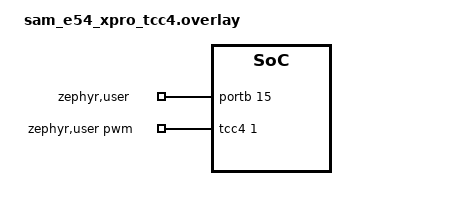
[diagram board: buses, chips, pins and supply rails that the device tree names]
/*
 * SPDX-FileCopyrightText: Copyright 2026 Microchip Technology Inc.
 * SPDX-License-Identifier: Apache-2.0
 */

/* connect PB14 to PB15 */

#define PWM_NODE    tcc4
#define PWM_PINCTRL tcc4_pwm_default
#define PWM_COMPAT "microchip,tcc-g1-pwm"
#include "mchp_pwm_loopback_support.dtsi"

/ {
	zephyr,user {
		pwms = <&tcc4 1 PWM_MSEC(20) 0>;
		gpios = <&portb 15 GPIO_ACTIVE_HIGH>;
	};
};

&portb {
	status = "okay";
};

&pinctrl {
	tcc4_pwm_default: tcc4_pwm_default {
		group1 {
			pinmux = <PB14F_TCC4_WO0>;
		};
	};
};
